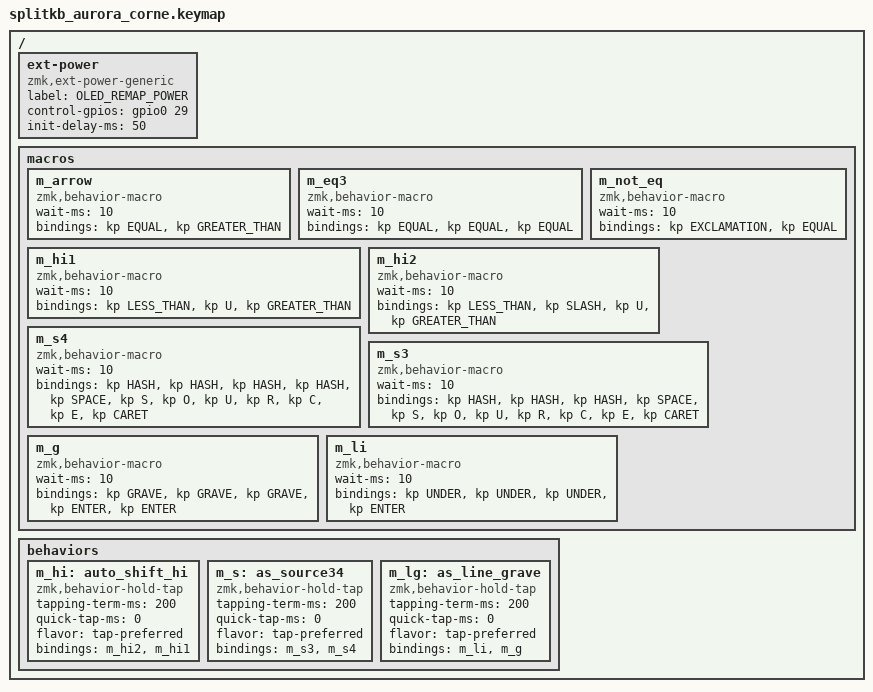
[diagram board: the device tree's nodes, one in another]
// Copyright 2022 Manna Harbour
// https://github.com/manna-harbour/miryoku
#include "zmk-helpers/helper.h"
#include "../miryoku/custom_config.h"
#include "../miryoku/mapping/42/corne.h"
#include "../miryoku/miryoku.dtsi"



/ {
    // Delete the original external power switch node if it exists
    /delete-node/ ext-power;

    // Re-create the external power node bound to pin P0.29
    ext-power {
        compatible = "zmk,ext-power-generic";
        label = "OLED_REMAP_POWER";
        control-gpios = <&gpio0 29 GPIO_ACTIVE_HIGH>;
        init-delay-ms = <50>;
    };

    // ... (υπάρχοντα behaviors ή keymaps του Corne)

    macros {
        m_arrow: m_arrow {
            compatible = "zmk,behavior-macro";
            #binding-cells = <0>;
            wait-ms = <10>;
            bindings = <&kp EQUAL>, <&kp GREATER_THAN>;
        };

        m_eq3: m_eq3 {
            compatible = "zmk,behavior-macro";
            #binding-cells = <0>;
            wait-ms = <10>;
            bindings = <&kp EQUAL>, <&kp EQUAL>, <&kp EQUAL>;
        };

        m_not_eq: m_not_eq {
            compatible = "zmk,behavior-macro";
            #binding-cells = <0>;
            wait-ms = <10>;
            bindings = <&kp EXCLAMATION>, <&kp EQUAL>;
        };
             // .... highlight obsidian
        m_hi1: m_hi1 {
            compatible = "zmk,behavior-macro";
            #binding-cells = <0>;
            wait-ms = <10>;
            bindings = <&kp LESS_THAN>, <&kp U>, <&kp GREATER_THAN>;
        };

        m_hi2: m_hi2 {
            compatible = "zmk,behavior-macro";
            #binding-cells = <0>;
            wait-ms = <10>;
            bindings = <&kp LESS_THAN>, <&kp SLASH>, <&kp U>, <&kp GREATER_THAN>;
        };

             // .... source obsidian
        m_s4: m_s4 {
            compatible = "zmk,behavior-macro";
            #binding-cells = <0>;
            wait-ms = <10>;
            bindings = <&kp HASH>, <&kp HASH>, <&kp HASH>, <&kp HASH>, <&kp SPACE>, <&kp S>, <&kp O>, <&kp U>, <&kp R>, <&kp  C>, <&kp E>, <&kp CARET>;
        };
        m_s3: m_s3 {
            compatible = "zmk,behavior-macro";
            #binding-cells = <0>;
            wait-ms = <10>;
            bindings = <&kp HASH>, <&kp HASH>, <&kp HASH>, <&kp SPACE>, <&kp S>, <&kp O>, <&kp U>, <&kp R>, <&kp  C>, <&kp E>, <&kp CARET>;
        };

             // .... grave line obsidian
        m_g: m_g {
            compatible = "zmk,behavior-macro";
            #binding-cells = <0>;
            wait-ms = <10>;
            bindings = <&kp GRAVE>, <&kp GRAVE>, <&kp GRAVE>, <&kp ENTER>, <&kp ENTER>;
        };
        m_li: m_li {
            compatible = "zmk,behavior-macro";
            #binding-cells = <0>;
            wait-ms = <10>;
            bindings = <&kp UNDER>, <&kp UNDER>, <&kp UNDER>, <&kp ENTER>;
        };
    };

    behaviors {
        // Hold-tap behavior: tap sends m_hi_tap, hold sends m_hi_hold
        m_hi: auto_shift_hi {
            compatible = "zmk,behavior-hold-tap";
            #binding-cells = <2>;
            tapping-term-ms = <200>;
            quick-tap-ms = <0>;
            flavor = "tap-preferred";
            bindings = <&m_hi2>, <&m_hi1>;
        };
        m_s: as_source34 {
            compatible = "zmk,behavior-hold-tap";
            #binding-cells = <2>;
            tapping-term-ms = <200>;
            quick-tap-ms = <0>;
            flavor = "tap-preferred";
            bindings = <&m_s3>, <&m_s4>;
        };
        m_lg: as_line_grave {
            compatible = "zmk,behavior-hold-tap";
            #binding-cells = <2>;
            tapping-term-ms = <200>;
            quick-tap-ms = <0>;
            flavor = "tap-preferred";
            bindings = <&m_li>, <&m_g>;
        };
    };
};

